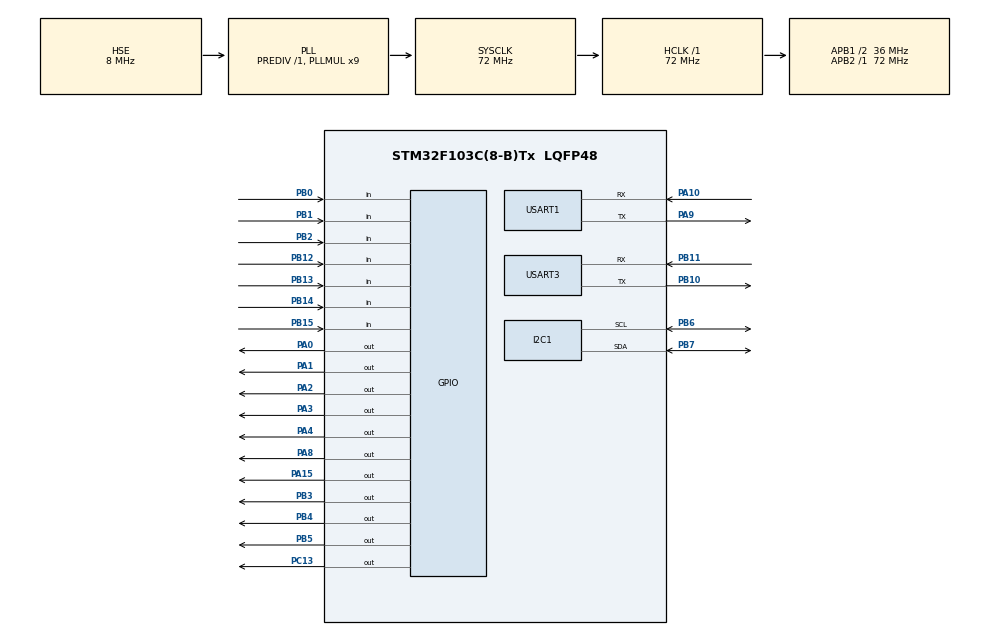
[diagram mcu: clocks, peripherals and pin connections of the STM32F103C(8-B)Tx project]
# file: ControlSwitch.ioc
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Dma.Request0=USART1_RX
Dma.Request1=USART1_TX
Dma.USART1_RX.0.Direction=DMA_PERIPH_TO_MEMORY
Dma.USART1_RX.0.Instance=DMA1_Channel5
Dma.USART1_RX.0.MemDataAlignment=DMA_MDATAALIGN_BYTE
Dma.USART1_RX.0.MemInc=DMA_MINC_ENABLE
Dma.USART1_RX.0.Mode=DMA_NORMAL
Dma.USART1_RX.0.PeriphDataAlignment=DMA_PDATAALIGN_BYTE
Dma.USART1_RX.0.PeriphInc=DMA_PINC_DISABLE
Dma.USART1_RX.0.Priority=DMA_PRIORITY_LOW
Dma.USART1_TX.1.Direction=DMA_MEMORY_TO_PERIPH
Dma.USART1_TX.1.Instance=DMA1_Channel4
Dma.USART1_TX.1.MemDataAlignment=DMA_MDATAALIGN_BYTE
Dma.USART1_TX.1.MemInc=DMA_MINC_ENABLE
Dma.USART1_TX.1.Mode=DMA_NORMAL
Dma.USART1_TX.1.PeriphDataAlignment=DMA_PDATAALIGN_BYTE
Dma.USART1_TX.1.PeriphInc=DMA_PINC_DISABLE
Dma.USART1_TX.1.Priority=DMA_PRIORITY_LOW
Mcu.Family=STM32F1
Mcu.Name=STM32F103C(8-B)Tx
Mcu.Package=LQFP48
NVIC.DMA1_Channel4_IRQn=true\:0\:0\:false\:false\:true\:false\:true
NVIC.DMA1_Channel5_IRQn=true\:0\:0\:false\:false\:true\:false\:true
NVIC.PriorityGroup=NVIC_PRIORITYGROUP_4
NVIC.TIM2_IRQn=true\:0\:0\:false\:false\:true\:true\:true
NVIC.TIM3_IRQn=true\:0\:0\:false\:false\:true\:true\:true
NVIC.USART1_IRQn=true\:0\:0\:false\:false\:true\:true\:true
NVIC.USART3_IRQn=true\:0\:0\:false\:false\:true\:true\:true
PA0-WKUP.Signal=GPIO_Output
PA1.Signal=GPIO_Output
PA10.Mode=Asynchronous
PA10.Signal=USART1_RX
PA13.Mode=Serial_Wire
PA13.Signal=SYS_JTMS-SWDIO
PA14.Mode=Serial_Wire
PA14.Signal=SYS_JTCK-SWCLK
PA15.Signal=GPIO_Output
PA2.Signal=GPIO_Output
PA3.Signal=GPIO_Output
PA4.Signal=GPIO_Output
PA8.GPIO_ModeDefaultOutputPP=GPIO_MODE_OUTPUT_OD
PA8.GPIO_PuPd=GPIO_NOPULL
PA8.GPIO_Speed=GPIO_SPEED_FREQ_LOW
PA8.Signal=GPIO_Output
PA9.Mode=Asynchronous
PA9.Signal=USART1_TX
PB0.Signal=GPIO_Input
PB1.Signal=GPIO_Input
PB10.Mode=Asynchronous
PB10.Signal=USART3_TX
PB11.Mode=Asynchronous
PB11.Signal=USART3_RX
PB12.Signal=GPIO_Input
PB13.Signal=GPIO_Input
PB14.Signal=GPIO_Input
PB15.Signal=GPIO_Input
PB2.Signal=GPIO_Input
PB3.Signal=GPIO_Output
PB4.Signal=GPIO_Output
PB5.Signal=GPIO_Output
PB6.Mode=I2C
PB6.Signal=I2C1_SCL
PB7.Mode=I2C
PB7.Signal=I2C1_SDA
PC13-TAMPER-RTC.Signal=GPIO_Output
PD0-OSC_IN.Mode=HSE-External-Oscillator
PD0-OSC_IN.Signal=RCC_OSC_IN
PD1-OSC_OUT.Mode=HSE-External-Oscillator
PD1-OSC_OUT.Signal=RCC_OSC_OUT
ProjectManager.HeapSize=0x200
ProjectManager.StackSize=0x400
ProjectManager.TargetToolchain=MDK-ARM V5.27
RCC.AHBFreq_Value=72000000
RCC.APB1CLKDivider=RCC_HCLK_DIV2
RCC.APB1Freq_Value=36000000
RCC.APB1TimFreq_Value=72000000
RCC.APB2Freq_Value=72000000
RCC.APB2TimFreq_Value=72000000
RCC.HCLKFreq_Value=72000000
RCC.PLLMUL=RCC_PLL_MUL9
RCC.PLLSourceVirtual=RCC_PLLSOURCE_HSE
RCC.SYSCLKFreq_VALUE=72000000
RCC.SYSCLKSource=RCC_SYSCLKSOURCE_PLLCLK
RCC.USBFreq_Value=72000000
TIM2.Period=1000-1
TIM2.Prescaler=36000-1
TIM3.AutoReloadPreload=TIM_AUTORELOAD_PRELOAD_ENABLE
TIM3.Period=1000-1
TIM3.Prescaler=36-1
USART1.VirtualMode=VM_ASYNC
USART3.VirtualMode=VM_ASYNC
VP_TIM2_VS_ClockSourceINT.Mode=Internal
VP_TIM3_VS_ClockSourceINT.Mode=Internal
board=custom

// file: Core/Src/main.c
/* USER CODE BEGIN Header */
/**
  ******************************************************************************
  * @file           : main.c
  * @brief          : Main program body
  ******************************************************************************
  * @attention
  *
  * <h2><center>&copy; Copyright (c) 2020 STMicroelectronics.
  * All rights reserved.</center></h2>
  *
  * This software component is licensed by ST under BSD 3-Clause license,
  * the "License"; You may not use this file except in compliance with the
  * License. You may obtain a copy of the License at:
  *                        opensource.org/licenses/BSD-3-Clause
  *
  * �?????????发芯片：stm32f103c8t6
  * �?????????发板：stm32f103c8t6�?????????小系统板
  *
  ******************************************************************************
  */
/* USER CODE END Header */
#include "main.h"

/* USER CODE BEGIN Includes */
#include "loop.h"
#include "stdio.h"
/* USER CODE END Includes */

I2C_HandleTypeDef hi2c1;

TIM_HandleTypeDef htim2;
TIM_HandleTypeDef htim3;

UART_HandleTypeDef huart1;
UART_HandleTypeDef huart3;
DMA_HandleTypeDef hdma_usart1_rx;
DMA_HandleTypeDef hdma_usart1_tx;

void SystemClock_Config(void);
static void MX_GPIO_Init(void);
static void MX_DMA_Init(void);
static void MX_I2C1_Init(void);
static void MX_USART1_UART_Init(void);
static void MX_TIM2_Init(void);
static void MX_TIM3_Init(void);
static void MX_USART3_UART_Init(void);

/* USER CODE BEGIN 0 */

/*
 * Redirect to UART3
 *
 *******************************************************************************/

int fputc(int ch, FILE *f)
{
	HAL_UART_Transmit(&huart3, (uint8_t *)&ch, 1, 0x00FF);
	return ch;
}
int fgetc(FILE * F)
{
  uint8_t ch_r;
  HAL_UART_Receive(&huart1, &ch_r, 1, 0xFFFF);
  return ch_r;
}

/* USER CODE END 0 */

int main(void)
{

  /* MCU Configuration--------------------------------------------------------*/

  /* Reset of all peripherals, Initializes the Flash interface and the Systick. */
  HAL_Init();

  /* Configure the system clock */
  SystemClock_Config();

  /* Initialize all configured peripherals */
  MX_GPIO_Init();
  MX_DMA_Init();
  MX_I2C1_Init();
  MX_USART1_UART_Init();
  MX_TIM2_Init();
  MX_TIM3_Init();
  MX_USART3_UART_Init();
  /* USER CODE BEGIN 2 */
  MAIN_Init();
  /* USER CODE END 2 */

  /* Infinite loop */
  /* USER CODE BEGIN WHILE */
  while (1)
  {
    MAIN_Loop();
    /* USER CODE END WHILE */

  }
}

void SystemClock_Config(void)
{
  RCC_OscInitTypeDef RCC_OscInitStruct = {0};
  RCC_ClkInitTypeDef RCC_ClkInitStruct = {0};

  /** Initializes the RCC Oscillators according to the specified parameters
  * in the RCC_OscInitTypeDef structure.
  */
  RCC_OscInitStruct.OscillatorType = RCC_OSCILLATORTYPE_HSE;
  RCC_OscInitStruct.HSEState = RCC_HSE_ON;
  RCC_OscInitStruct.HSEPredivValue = RCC_HSE_PREDIV_DIV1;
  RCC_OscInitStruct.HSIState = RCC_HSI_ON;
  RCC_OscInitStruct.PLL.PLLState = RCC_PLL_ON;
  RCC_OscInitStruct.PLL.PLLSource = RCC_PLLSOURCE_HSE;
  RCC_OscInitStruct.PLL.PLLMUL = RCC_PLL_MUL9;
  if (HAL_RCC_OscConfig(&RCC_OscInitStruct) != HAL_OK)
  {
    Error_Handler();
  }
  /** Initializes the CPU, AHB and APB buses clocks
  */
  RCC_ClkInitStruct.ClockType = RCC_CLOCKTYPE_HCLK|RCC_CLOCKTYPE_SYSCLK
                              |RCC_CLOCKTYPE_PCLK1|RCC_CLOCKTYPE_PCLK2;
  RCC_ClkInitStruct.SYSCLKSource = RCC_SYSCLKSOURCE_PLLCLK;
  RCC_ClkInitStruct.AHBCLKDivider = RCC_SYSCLK_DIV1;
  RCC_ClkInitStruct.APB1CLKDivider = RCC_HCLK_DIV2;
  RCC_ClkInitStruct.APB2CLKDivider = RCC_HCLK_DIV1;

  if (HAL_RCC_ClockConfig(&RCC_ClkInitStruct, FLASH_LATENCY_2) != HAL_OK)
  {
    Error_Handler();
  }
}

static void MX_I2C1_Init(void)
{

  hi2c1.Instance = I2C1;
  hi2c1.Init.ClockSpeed = 100000;
  hi2c1.Init.DutyCycle = I2C_DUTYCYCLE_2;
  hi2c1.Init.OwnAddress1 = 0;
  hi2c1.Init.AddressingMode = I2C_ADDRESSINGMODE_7BIT;
  hi2c1.Init.DualAddressMode = I2C_DUALADDRESS_DISABLE;
  hi2c1.Init.OwnAddress2 = 0;
  hi2c1.Init.GeneralCallMode = I2C_GENERALCALL_DISABLE;
  hi2c1.Init.NoStretchMode = I2C_NOSTRETCH_DISABLE;
  if (HAL_I2C_Init(&hi2c1) != HAL_OK)
  {
    Error_Handler();
  }

}

static void MX_TIM2_Init(void)
{

  TIM_ClockConfigTypeDef sClockSourceConfig = {0};
  TIM_MasterConfigTypeDef sMasterConfig = {0};

  htim2.Instance = TIM2;
  htim2.Init.Prescaler = 36000-1;
  htim2.Init.CounterMode = TIM_COUNTERMODE_UP;
  htim2.Init.Period = 1000-1;
  htim2.Init.ClockDivision = TIM_CLOCKDIVISION_DIV1;
  htim2.Init.AutoReloadPreload = TIM_AUTORELOAD_PRELOAD_DISABLE;
  if (HAL_TIM_Base_Init(&htim2) != HAL_OK)
  {
    Error_Handler();
  }
  sClockSourceConfig.ClockSource = TIM_CLOCKSOURCE_INTERNAL;
  if (HAL_TIM_ConfigClockSource(&htim2, &sClockSourceConfig) != HAL_OK)
  {
    Error_Handler();
  }
  sMasterConfig.MasterOutputTrigger = TIM_TRGO_RESET;
  sMasterConfig.MasterSlaveMode = TIM_MASTERSLAVEMODE_DISABLE;
  if (HAL_TIMEx_MasterConfigSynchronization(&htim2, &sMasterConfig) != HAL_OK)
  {
    Error_Handler();
  }

}

static void MX_TIM3_Init(void)
{

  TIM_ClockConfigTypeDef sClockSourceConfig = {0};
  TIM_MasterConfigTypeDef sMasterConfig = {0};

  htim3.Instance = TIM3;
  htim3.Init.Prescaler = 36-1;
  htim3.Init.CounterMode = TIM_COUNTERMODE_UP;
  htim3.Init.Period = 1000-1;
  htim3.Init.ClockDivision = TIM_CLOCKDIVISION_DIV1;
  htim3.Init.AutoReloadPreload = TIM_AUTORELOAD_PRELOAD_ENABLE;
  if (HAL_TIM_Base_Init(&htim3) != HAL_OK)
  {
    Error_Handler();
  }
  sClockSourceConfig.ClockSource = TIM_CLOCKSOURCE_INTERNAL;
  if (HAL_TIM_ConfigClockSource(&htim3, &sClockSourceConfig) != HAL_OK)
  {
    Error_Handler();
  }
  sMasterConfig.MasterOutputTrigger = TIM_TRGO_RESET;
  sMasterConfig.MasterSlaveMode = TIM_MASTERSLAVEMODE_DISABLE;
  if (HAL_TIMEx_MasterConfigSynchronization(&htim3, &sMasterConfig) != HAL_OK)
  {
    Error_Handler();
  }

}

static void MX_USART1_UART_Init(void)
{

  huart1.Instance = USART1;
  huart1.Init.BaudRate = 115200;
  huart1.Init.WordLength = UART_WORDLENGTH_8B;
  huart1.Init.StopBits = UART_STOPBITS_1;
  huart1.Init.Parity = UART_PARITY_NONE;
  huart1.Init.Mode = UART_MODE_TX_RX;
  huart1.Init.HwFlowCtl = UART_HWCONTROL_NONE;
  huart1.Init.OverSampling = UART_OVERSAMPLING_16;
  if (HAL_UART_Init(&huart1) != HAL_OK)
  {
    Error_Handler();
  }

}

static void MX_USART3_UART_Init(void)
{

  huart3.Instance = USART3;
  huart3.Init.BaudRate = 115200;
  huart3.Init.WordLength = UART_WORDLENGTH_8B;
  huart3.Init.StopBits = UART_STOPBITS_1;
  huart3.Init.Parity = UART_PARITY_NONE;
  huart3.Init.Mode = UART_MODE_TX_RX;
  huart3.Init.HwFlowCtl = UART_HWCONTROL_NONE;
  huart3.Init.OverSampling = UART_OVERSAMPLING_16;
  if (HAL_UART_Init(&huart3) != HAL_OK)
  {
    Error_Handler();
  }

}

static void MX_DMA_Init(void)
{

  /* DMA controller clock enable */
  __HAL_RCC_DMA1_CLK_ENABLE();

  /* DMA interrupt init */
  /* DMA1_Channel4_IRQn interrupt configuration */
  HAL_NVIC_SetPriority(DMA1_Channel4_IRQn, 0, 0);
  HAL_NVIC_EnableIRQ(DMA1_Channel4_IRQn);
  /* DMA1_Channel5_IRQn interrupt configuration */
  HAL_NVIC_SetPriority(DMA1_Channel5_IRQn, 0, 0);
  HAL_NVIC_EnableIRQ(DMA1_Channel5_IRQn);

}

static void MX_GPIO_Init(void)
{
  GPIO_InitTypeDef GPIO_InitStruct = {0};

  /* GPIO Ports Clock Enable */
  __HAL_RCC_GPIOC_CLK_ENABLE();
  __HAL_RCC_GPIOD_CLK_ENABLE();
  __HAL_RCC_GPIOA_CLK_ENABLE();
  __HAL_RCC_GPIOB_CLK_ENABLE();

  /*Configure GPIO pin Output Level */
  HAL_GPIO_WritePin(GPIOC, GPIO_PIN_13, GPIO_PIN_RESET);

  /*Configure GPIO pin Output Level */
  HAL_GPIO_WritePin(GPIOA, GPIO_PIN_0|GPIO_PIN_1|GPIO_PIN_2|GPIO_PIN_3
                          |GPIO_PIN_4|GPIO_PIN_8|GPIO_PIN_15, GPIO_PIN_RESET);

  /*Configure GPIO pin Output Level */
  HAL_GPIO_WritePin(GPIOB, GPIO_PIN_3|GPIO_PIN_4|GPIO_PIN_5, GPIO_PIN_RESET);

  /*Configure GPIO pin : PC13 */
  GPIO_InitStruct.Pin = GPIO_PIN_13;
  GPIO_InitStruct.Mode = GPIO_MODE_OUTPUT_PP;
  GPIO_InitStruct.Pull = GPIO_NOPULL;
  GPIO_InitStruct.Speed = GPIO_SPEED_FREQ_LOW;
  HAL_GPIO_Init(GPIOC, &GPIO_InitStruct);

  /*Configure GPIO pins : PA0 PA1 PA2 PA3
                           PA4 PA15 */
  GPIO_InitStruct.Pin = GPIO_PIN_0|GPIO_PIN_1|GPIO_PIN_2|GPIO_PIN_3
                          |GPIO_PIN_4|GPIO_PIN_15;
  GPIO_InitStruct.Mode = GPIO_MODE_OUTPUT_PP;
  GPIO_InitStruct.Pull = GPIO_NOPULL;
  GPIO_InitStruct.Speed = GPIO_SPEED_FREQ_LOW;
  HAL_GPIO_Init(GPIOA, &GPIO_InitStruct);

  /*Configure GPIO pins : PB0 PB1 PB2 PB12
                           PB13 PB14 PB15 */
  GPIO_InitStruct.Pin = GPIO_PIN_0|GPIO_PIN_1|GPIO_PIN_2|GPIO_PIN_12
                          |GPIO_PIN_13|GPIO_PIN_14|GPIO_PIN_15;
  GPIO_InitStruct.Mode = GPIO_MODE_INPUT;
  GPIO_InitStruct.Pull = GPIO_NOPULL;
  HAL_GPIO_Init(GPIOB, &GPIO_InitStruct);

  /*Configure GPIO pin : PA8 */
  GPIO_InitStruct.Pin = GPIO_PIN_8;
  GPIO_InitStruct.Mode = GPIO_MODE_OUTPUT_OD;
  GPIO_InitStruct.Pull = GPIO_NOPULL;
  GPIO_InitStruct.Speed = GPIO_SPEED_FREQ_LOW;
  HAL_GPIO_Init(GPIOA, &GPIO_InitStruct);

  /*Configure GPIO pins : PB3 PB4 PB5 */
  GPIO_InitStruct.Pin = GPIO_PIN_3|GPIO_PIN_4|GPIO_PIN_5;
  GPIO_InitStruct.Mode = GPIO_MODE_OUTPUT_PP;
  GPIO_InitStruct.Pull = GPIO_NOPULL;
  GPIO_InitStruct.Speed = GPIO_SPEED_FREQ_LOW;
  HAL_GPIO_Init(GPIOB, &GPIO_InitStruct);

}

void Error_Handler(void)
{
}

/************************ (C) COPYRIGHT STMicroelectronics *****END OF FILE****/
